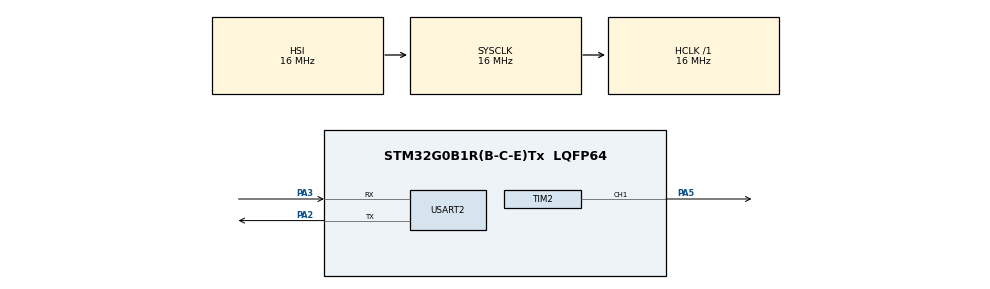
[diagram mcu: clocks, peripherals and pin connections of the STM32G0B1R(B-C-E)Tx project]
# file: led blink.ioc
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Mcu.Family=STM32G0
Mcu.Name=STM32G0B1R(B-C-E)Tx
Mcu.Package=LQFP64
PA2.Mode=Asynchronous
PA2.Signal=USART2_TX
PA3.Mode=Asynchronous
PA3.Signal=USART2_RX
PA5.Signal=S_TIM2_CH1_ETR
ProjectManager.HeapSize=0x200
ProjectManager.StackSize=0x400
ProjectManager.TargetToolchain=STM32CubeIDE
RCC.AHBFreq_Value=16000000
RCC.CortexFreq_Value=16000000
RCC.EXTERNAL_CLOCK_VALUE=12288000
RCC.HCLKFreq_Value=16000000
RCC.HSE_VALUE=8000000
RCC.HSI48_VALUE=48000000
RCC.HSI_VALUE=16000000
RCC.LSE_VALUE=32768
RCC.SYSCLKFreq_VALUE=16000000
RCC.USBFreq_Value=48000000
RCC.VCOOutputFreq_Value=128000000
SH.S_TIM2_CH1_ETR.0=TIM2_CH1,PWM Generation1 CH1
TIM2.Channel-PWM\ Generation1\ CH1=TIM_CHANNEL_1
TIM2.Period=999
TIM2.Prescaler=15
USART2.VirtualMode-Asynchronous=VM_ASYNC
VP_SYS_VS_DBSignals.Mode=DisableDeadBatterySignals
board=NUCLEO-G0B1RE

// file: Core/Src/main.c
/* USER CODE BEGIN Header */
/**
  ******************************************************************************
  * @file           : main.c
  * @brief          : Main program body
  ******************************************************************************
  * @attention
  *
  * Copyright (c) 2026 STMicroelectronics.
  * All rights reserved.
  *
  ******************************************************************************
  */
/* USER CODE END Header */

#include "main.h"
#include <stdlib.h>
#include <string.h>
#include <stdio.h>

TIM_HandleTypeDef htim2;
UART_HandleTypeDef huart2;

void SystemClock_Config(void);
static void MX_GPIO_Init(void);
static void MX_TIM2_Init(void);
static void MX_USART2_UART_Init(void);

int main(void)
{

  /* MCU Configuration--------------------------------------------------------*/

  HAL_Init();

  SystemClock_Config();

  /* Initialize all configured peripherals */
  MX_GPIO_Init();
  MX_TIM2_Init();
  MX_USART2_UART_Init();

  /* USER CODE BEGIN 2 */

  /* Start PWM */
  HAL_TIM_PWM_Start(&htim2, TIM_CHANNEL_1);

  char rx_buffer[10];
  char message[50];
  uint8_t rx_byte;
  uint8_t index = 0;
  int brightness = 0;
  uint32_t compare_value;

  /* Welcome message */
  char welcome[] =
      "\r\nPWM LED Brightness Control\r\n"
      "Enter brightness (0-100): ";

  HAL_UART_Transmit(&huart2,
                    (uint8_t *)welcome,
                    strlen(welcome),
                    HAL_MAX_DELAY);

  /* USER CODE END 2 */

  /* Infinite loop */
  /* USER CODE BEGIN WHILE */
  while (1)
  {
    /* Receive one character from Tera Term */
    HAL_UART_Receive(&huart2, &rx_byte, 1, HAL_MAX_DELAY);

    /* Check for Enter key */
    if (rx_byte == '\r' || rx_byte == '\n')
    {
      if (index > 0)
      {
        rx_buffer[index] = '\0';

        /* Convert received text to integer */
        brightness = atoi(rx_buffer);

        /* Limit brightness between 0 and 100 */
        if (brightness < 0)
        {
          brightness = 0;
        }

        if (brightness > 100)
        {
          brightness = 100;
        }

        /* Convert percentage to PWM compare value */
        compare_value = (brightness * 999) / 100;

        /* Set PWM brightness */
        __HAL_TIM_SET_COMPARE(&htim2,
                              TIM_CHANNEL_1,
                              compare_value);

        /* Send confirmation to Tera Term */
        sprintf(message,
                "\r\nBrightness set to %d%%\r\n"
                "Enter brightness (0-100): ",
                brightness);

        HAL_UART_Transmit(&huart2,
                          (uint8_t *)message,
                          strlen(message),
                          HAL_MAX_DELAY);

        /* Reset buffer */
        index = 0;
      }
    }
    else
    {
      /* Store received character */
      if (index < sizeof(rx_buffer) - 1)
      {
        rx_buffer[index++] = rx_byte;

        /* Echo character to Tera Term */
        HAL_UART_Transmit(&huart2,
                          &rx_byte,
                          1,
                          HAL_MAX_DELAY);
      }
    }
  }
  /* USER CODE END WHILE */
}

void SystemClock_Config(void)
{
  RCC_OscInitTypeDef RCC_OscInitStruct = {0};
  RCC_ClkInitTypeDef RCC_ClkInitStruct = {0};

  HAL_PWREx_ControlVoltageScaling(PWR_REGULATOR_VOLTAGE_SCALE1);

  RCC_OscInitStruct.OscillatorType = RCC_OSCILLATORTYPE_HSI;
  RCC_OscInitStruct.HSIState = RCC_HSI_ON;
  RCC_OscInitStruct.HSIDiv = RCC_HSI_DIV1;
  RCC_OscInitStruct.HSICalibrationValue = RCC_HSICALIBRATION_DEFAULT;
  RCC_OscInitStruct.PLL.PLLState = RCC_PLL_NONE;

  if (HAL_RCC_OscConfig(&RCC_OscInitStruct) != HAL_OK)
  {
    Error_Handler();
  }

  RCC_ClkInitStruct.ClockType = RCC_CLOCKTYPE_HCLK |
                                RCC_CLOCKTYPE_SYSCLK |
                                RCC_CLOCKTYPE_PCLK1;

  RCC_ClkInitStruct.SYSCLKSource = RCC_SYSCLKSOURCE_HSI;
  RCC_ClkInitStruct.AHBCLKDivider = RCC_SYSCLK_DIV1;
  RCC_ClkInitStruct.APB1CLKDivider = RCC_HCLK_DIV1;

  if (HAL_RCC_ClockConfig(&RCC_ClkInitStruct, FLASH_LATENCY_0) != HAL_OK)
  {
    Error_Handler();
  }
}

static void MX_TIM2_Init(void)
{
  TIM_MasterConfigTypeDef sMasterConfig = {0};
  TIM_OC_InitTypeDef sConfigOC = {0};

  htim2.Instance = TIM2;
  htim2.Init.Prescaler = 15;
  htim2.Init.CounterMode = TIM_COUNTERMODE_UP;
  htim2.Init.Period = 999;
  htim2.Init.ClockDivision = TIM_CLOCKDIVISION_DIV1;
  htim2.Init.AutoReloadPreload = TIM_AUTORELOAD_PRELOAD_DISABLE;

  if (HAL_TIM_PWM_Init(&htim2) != HAL_OK)
  {
    Error_Handler();
  }

  sMasterConfig.MasterOutputTrigger = TIM_TRGO_RESET;
  sMasterConfig.MasterSlaveMode = TIM_MASTERSLAVEMODE_DISABLE;

  if (HAL_TIMEx_MasterConfigSynchronization(&htim2,
                                            &sMasterConfig) != HAL_OK)
  {
    Error_Handler();
  }

  sConfigOC.OCMode = TIM_OCMODE_PWM1;
  sConfigOC.Pulse = 0;
  sConfigOC.OCPolarity = TIM_OCPOLARITY_HIGH;
  sConfigOC.OCFastMode = TIM_OCFAST_DISABLE;

  if (HAL_TIM_PWM_ConfigChannel(&htim2,
                                &sConfigOC,
                                TIM_CHANNEL_1) != HAL_OK)
  {
    Error_Handler();
  }

  HAL_TIM_MspPostInit(&htim2);
}

static void MX_USART2_UART_Init(void)
{
  huart2.Instance = USART2;
  huart2.Init.BaudRate = 115200;
  huart2.Init.WordLength = UART_WORDLENGTH_8B;
  huart2.Init.StopBits = UART_STOPBITS_1;
  huart2.Init.Parity = UART_PARITY_NONE;
  huart2.Init.Mode = UART_MODE_TX_RX;
  huart2.Init.HwFlowCtl = UART_HWCONTROL_NONE;
  huart2.Init.OverSampling = UART_OVERSAMPLING_16;
  huart2.Init.OneBitSampling = UART_ONE_BIT_SAMPLE_DISABLE;
  huart2.Init.ClockPrescaler = UART_PRESCALER_DIV1;
  huart2.AdvancedInit.AdvFeatureInit = UART_ADVFEATURE_NO_INIT;

  if (HAL_UART_Init(&huart2) != HAL_OK)
  {
    Error_Handler();
  }

  if (HAL_UARTEx_SetTxFifoThreshold(&huart2,
                                    UART_TXFIFO_THRESHOLD_1_8) != HAL_OK)
  {
    Error_Handler();
  }

  if (HAL_UARTEx_SetRxFifoThreshold(&huart2,
                                    UART_RXFIFO_THRESHOLD_1_8) != HAL_OK)
  {
    Error_Handler();
  }

  if (HAL_UARTEx_DisableFifoMode(&huart2) != HAL_OK)
  {
    Error_Handler();
  }
}

static void MX_GPIO_Init(void)
{
  __HAL_RCC_GPIOA_CLK_ENABLE();
}

void Error_Handler(void)
{
  __disable_irq();

  while (1)
  {
  }
}
